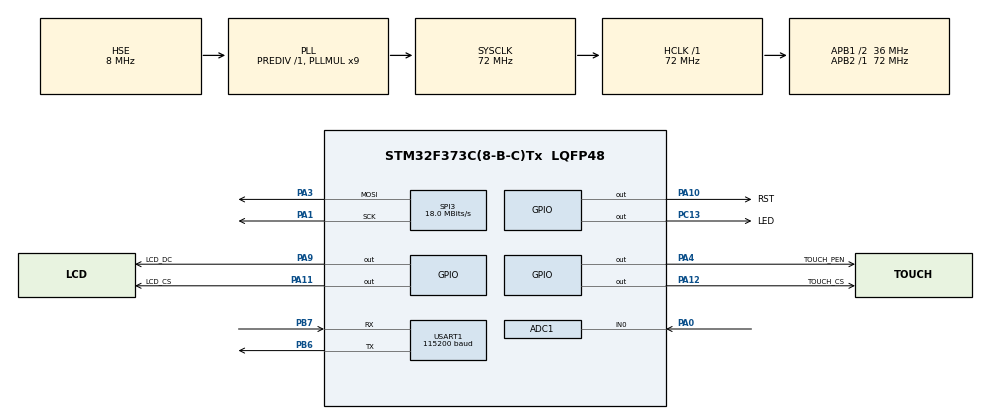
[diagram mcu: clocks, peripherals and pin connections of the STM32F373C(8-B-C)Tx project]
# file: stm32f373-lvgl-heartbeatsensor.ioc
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ADC1.Channel-46\#ChannelRegularConversion=ADC_CHANNEL_0
ADC1.ContinuousConvMode=DISABLE
ADC1.DataAlign=ADC_DATAALIGN_RIGHT
ADC1.DiscontinuousConvMode=DISABLE
ADC1.EnableAnalogWatchDog=false
ADC1.EnableRegularConversion=ENABLE
ADC1.ExternalTrigConv=ADC_EXTERNALTRIGCONV_T2_CC2
ADC1.InjNumberOfConversion=0
ADC1.NbrOfConversion=1
ADC1.NbrOfConversionFlag=1
ADC1.Rank-46\#ChannelRegularConversion=1
ADC1.SamplingTime-46\#ChannelRegularConversion=ADC_SAMPLETIME_1CYCLE_5
ADC1.ScanConvMode=ADC_SCAN_DISABLE
ADC1.master=1
Mcu.Family=STM32F3
Mcu.Name=STM32F373C(8-B-C)Tx
Mcu.Package=LQFP48
NVIC.ADC1_IRQn=true\:0\:0\:false\:false\:true\:true
NVIC.PriorityGroup=NVIC_PRIORITYGROUP_4
NVIC.TIM2_IRQn=true\:0\:0\:false\:false\:true\:true
PA0.Mode=IN0
PA0.Signal=ADC1_IN0
PA1.Mode=TX_Only_Simplex_Unidirect_Master
PA1.Signal=SPI3_SCK
PA10.GPIO_Label=RST
PA10.Signal=GPIO_Output
PA11.GPIO_Label=LCD_CS
PA11.Signal=GPIO_Output
PA12.GPIO_Label=TOUCH_CS
PA12.Signal=GPIO_Output
PA13.Mode=Serial_Wire
PA13.Signal=SYS_JTMS-SWDIO
PA14.Mode=Serial_Wire
PA14.Signal=SYS_JTCK-SWCLK
PA2.Signal=SPI3_MISO
PA3.Mode=TX_Only_Simplex_Unidirect_Master
PA3.Signal=SPI3_MOSI
PA4.GPIO_Label=TOUCH_PEN
PA4.Signal=GPIO_Output
PA9.GPIO_Label=LCD_DC
PA9.Signal=GPIO_Output
PB6.Mode=Asynchronous
PB6.Signal=USART1_TX
PB7.Mode=Asynchronous
PB7.Signal=USART1_RX
PC13.GPIO_Label=LED
PC13.Signal=GPIO_Output
PF0-OSC_IN.Mode=HSE-External-Oscillator
PF0-OSC_IN.Signal=RCC_OSC_IN
PF1-OSC_OUT.Mode=HSE-External-Oscillator
PF1-OSC_OUT.Signal=RCC_OSC_OUT
ProjectManager.HeapSize=0x200
ProjectManager.StackSize=0x400
ProjectManager.TargetToolchain=Other Toolchains (GPDSC)
RCC.AHBFreq_Value=72000000
RCC.APB1CLKDivider=RCC_HCLK_DIV2
RCC.APB1Freq_Value=36000000
RCC.APB1TimFreq_Value=72000000
RCC.APB2Freq_Value=72000000
RCC.APB2TimFreq_Value=72000000
RCC.CortexFreq_Value=72000000
RCC.HCLKFreq_Value=72000000
RCC.HSE_VALUE=8000000
RCC.HSI_VALUE=8000000
RCC.LSE_VALUE=32768
RCC.PLLMUL=RCC_PLL_MUL9
RCC.PLLSourceVirtual=RCC_PLLSOURCE_HSE
RCC.SDADCPresc=RCC_SDADCSYSCLK_DIV12
RCC.SYSCLKFreq_VALUE=72000000
RCC.SYSCLKSource=RCC_SYSCLKSOURCE_PLLCLK
RCC.USBFreq_Value=72000000
SPI3.BaudRatePrescaler=SPI_BAUDRATEPRESCALER_2
SPI3.CalculateBaudRate=18.0 MBits/s
SPI3.DataSize=SPI_DATASIZE_8BIT
SPI3.Direction=SPI_DIRECTION_2LINES
SPI3.Mode=SPI_MODE_MASTER
SPI3.VirtualType=VM_MASTER
TIM2.AutoReloadPreload=TIM_AUTORELOAD_PRELOAD_ENABLE
TIM2.Channel-Output\ Compare2\ No\ Output=TIM_CHANNEL_2
TIM2.OCMode_2=TIM_OCMODE_TOGGLE
TIM2.Period=9000-1
TIM2.Prescaler=100-1
TIM2.TIM_MasterOutputTrigger=TIM_TRGO_OC2REF
USART1.BaudRate=115200
USART1.VirtualMode-Asynchronous=VM_ASYNC
VP_TIM2_VS_ClockSourceINT.Mode=Internal
VP_TIM2_VS_no_output2.Mode=Output Compare2 No Output
board=custom

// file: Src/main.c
/**
  ******************************************************************************
  * @file           : main.c
  * @brief          : Main program body
  ******************************************************************************
  ** This notice applies to any and all portions of this file
  * that are not between comment pairs USER CODE BEGIN and
  * USER CODE END. Other portions of this file, whether
  * inserted by the user or by software development tools
  * are owned by their respective copyright owners.
  *
  * COPYRIGHT(c) 2020 STMicroelectronics
  *
  * Redistribution and use in source and binary forms, with or without modification,
  * are permitted provided that the following conditions are met:
  *   1. Redistributions of source code must retain the above copyright notice,
  *      this list of conditions and the following disclaimer.
  *   2. Redistributions in binary form must reproduce the above copyright notice,
  *      this list of conditions and the following disclaimer in the documentation
  *      and/or other materials provided with the distribution.
  *   3. Neither the name of STMicroelectronics nor the names of its contributors
  *      may be used to endorse or promote products derived from this software
  *      without specific prior written permission.
  *
  * THIS SOFTWARE IS PROVIDED BY THE COPYRIGHT HOLDERS AND CONTRIBUTORS "AS IS"
  * AND ANY EXPRESS OR IMPLIED WARRANTIES, INCLUDING, BUT NOT LIMITED TO, THE
  * IMPLIED WARRANTIES OF MERCHANTABILITY AND FITNESS FOR A PARTICULAR PURPOSE ARE
  * DISCLAIMED. IN NO EVENT SHALL THE COPYRIGHT HOLDER OR CONTRIBUTORS BE LIABLE
  * FOR ANY DIRECT, INDIRECT, INCIDENTAL, SPECIAL, EXEMPLARY, OR CONSEQUENTIAL
  * DAMAGES (INCLUDING, BUT NOT LIMITED TO, PROCUREMENT OF SUBSTITUTE GOODS OR
  * SERVICES; LOSS OF USE, DATA, OR PROFITS; OR BUSINESS INTERRUPTION) HOWEVER
  * CAUSED AND ON ANY THEORY OF LIABILITY, WHETHER IN CONTRACT, STRICT LIABILITY,
  * OR TORT (INCLUDING NEGLIGENCE OR OTHERWISE) ARISING IN ANY WAY OUT OF THE USE
  * OF THIS SOFTWARE, EVEN IF ADVISED OF THE POSSIBILITY OF SUCH DAMAGE.
  *
  ******************************************************************************
  */
#include "main.h"
#include "stm32f3xx_hal.h"
#include "adc.h"
#include "spi.h"
#include "tim.h"
#include "usart.h"
#include "gpio.h"

/* USER CODE BEGIN Includes */
#include "lv.h"
/* USER CODE END Includes */

/* USER CODE BEGIN PV */
/* Private variables ---------------------------------------------------------*/

/* USER CODE END PV */

void SystemClock_Config(void);

/* USER CODE BEGIN PFP */
/* Private function prototypes -----------------------------------------------*/

/* USER CODE END PFP */

int main(void)
{

  /* MCU Configuration----------------------------------------------------------*/

  /* Reset of all peripherals, Initializes the Flash interface and the Systick. */
  HAL_Init();

  /* Configure the system clock */
  SystemClock_Config();

  /* Initialize all configured peripherals */
  MX_GPIO_Init();
  MX_USART1_UART_Init();
  MX_SPI3_Init();
  MX_TIM2_Init();
  MX_ADC1_Init();
  /* USER CODE BEGIN 2 */
  lv_setup();

  /* USER CODE END 2 */

  /* Infinite loop */
  /* USER CODE BEGIN WHILE */
  while (1)
  {

    lv_loop();
  /* USER CODE END WHILE */

  }

}

void SystemClock_Config(void)
{

  RCC_OscInitTypeDef RCC_OscInitStruct;
  RCC_ClkInitTypeDef RCC_ClkInitStruct;
  RCC_PeriphCLKInitTypeDef PeriphClkInit;

    /**Initializes the CPU, AHB and APB busses clocks
    */
  RCC_OscInitStruct.OscillatorType = RCC_OSCILLATORTYPE_HSE;
  RCC_OscInitStruct.HSEState = RCC_HSE_ON;
  RCC_OscInitStruct.HSEPredivValue = RCC_HSE_PREDIV_DIV1;
  RCC_OscInitStruct.HSIState = RCC_HSI_ON;
  RCC_OscInitStruct.PLL.PLLState = RCC_PLL_ON;
  RCC_OscInitStruct.PLL.PLLSource = RCC_PLLSOURCE_HSE;
  RCC_OscInitStruct.PLL.PLLMUL = RCC_PLL_MUL9;
  if (HAL_RCC_OscConfig(&RCC_OscInitStruct) != HAL_OK)
  {
    _Error_Handler(__FILE__, __LINE__);
  }

    /**Initializes the CPU, AHB and APB busses clocks
    */
  RCC_ClkInitStruct.ClockType = RCC_CLOCKTYPE_HCLK|RCC_CLOCKTYPE_SYSCLK
                              |RCC_CLOCKTYPE_PCLK1|RCC_CLOCKTYPE_PCLK2;
  RCC_ClkInitStruct.SYSCLKSource = RCC_SYSCLKSOURCE_PLLCLK;
  RCC_ClkInitStruct.AHBCLKDivider = RCC_SYSCLK_DIV1;
  RCC_ClkInitStruct.APB1CLKDivider = RCC_HCLK_DIV2;
  RCC_ClkInitStruct.APB2CLKDivider = RCC_HCLK_DIV1;

  if (HAL_RCC_ClockConfig(&RCC_ClkInitStruct, FLASH_LATENCY_2) != HAL_OK)
  {
    _Error_Handler(__FILE__, __LINE__);
  }

  PeriphClkInit.PeriphClockSelection = RCC_PERIPHCLK_USART1|RCC_PERIPHCLK_ADC1;
  PeriphClkInit.Usart1ClockSelection = RCC_USART1CLKSOURCE_PCLK2;
  PeriphClkInit.Adc1ClockSelection = RCC_ADC1PCLK2_DIV2;

  if (HAL_RCCEx_PeriphCLKConfig(&PeriphClkInit) != HAL_OK)
  {
    _Error_Handler(__FILE__, __LINE__);
  }

    /**Configure the Systick interrupt time
    */
  HAL_SYSTICK_Config(HAL_RCC_GetHCLKFreq()/1000);

    /**Configure the Systick
    */
  HAL_SYSTICK_CLKSourceConfig(SYSTICK_CLKSOURCE_HCLK);

  /* SysTick_IRQn interrupt configuration */
  HAL_NVIC_SetPriority(SysTick_IRQn, 0, 0);
}

void _Error_Handler(char *file, int line)
{
  while (1)
  {
  }
}

/************************ (C) COPYRIGHT STMicroelectronics *****END OF FILE****/
